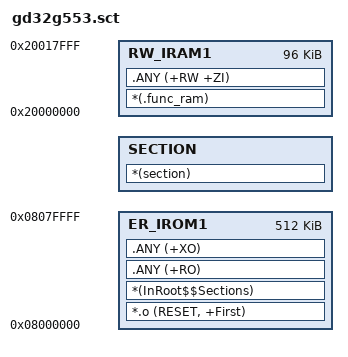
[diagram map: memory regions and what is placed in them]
; *************************************************************
; *** Scatter-Loading Description File for GD32G553 Keil MDK ***
; *************************************************************

LR_IROM1 0x08000000 0x00080000  {
  ER_IROM1 0x08000000 0x00080000  {
   *.o (RESET, +First)
   *(InRoot$$Sections)
   .ANY (+RO)
   .ANY (+XO)
  }
  SECTION +0 {
   *(section)
  }
  RW_IRAM1 0x20000000 0x00018000  {
   *(.func_ram)
   .ANY (+RW +ZI)
  }
}
